# RP2350 register map
Vendor: Raspberry Pi; Series: RP; File version: 0.1
CPU: CM33 r1p0, little endian, MPU, FPU, DSP, VTOR, 4 interrupt priority bits, 52 interrupts, 8 SAU regions
Registers are 32-bit, read-write, reset 0x0 unless marked. A register's access mark holds for its fields unless they carry their own. Offsets are from the block's base; [hi:lo] are bit positions; {n}, {i} and the like mark numbered series; 'fields as' and 'values as' point back to an identical list; <NAME> marks a mode.

## TICKS — Peripheral description
Base 0x40108000
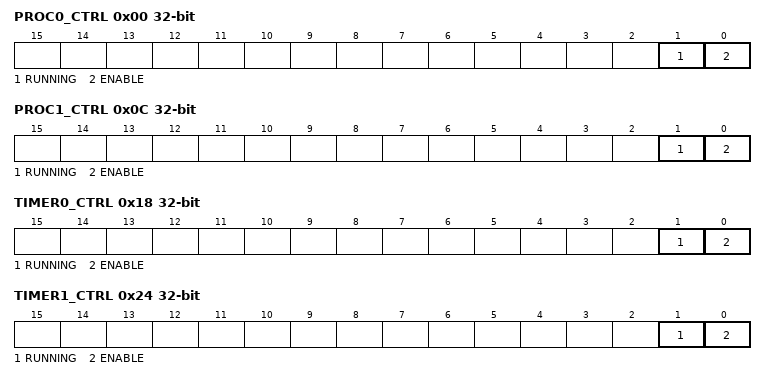
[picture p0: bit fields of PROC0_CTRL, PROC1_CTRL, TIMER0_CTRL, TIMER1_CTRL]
0x00 PROC0_CTRL — Controls the tick generator
  [1] RUNNING ro — Is the tick generator running?
  [0] ENABLE — start / stop tick generation
0x04 PROC0_CYCLES — register description
  [8:0] PROC0_CYCLES — Total number of clk_tick cycles before the next tick.
0x08 PROC0_COUNT reset not defined — register description
  [8:0] PROC0_COUNT ro — Count down timer: the remaining number clk_tick cycles before the next tick is generated.
0x0C PROC1_CTRL — Controls the tick generator
  fields as PROC0_CTRL
0x10 PROC1_CYCLES — register description
  [8:0] PROC1_CYCLES — Total number of clk_tick cycles before the next tick.
0x14 PROC1_COUNT reset not defined — register description
  [8:0] PROC1_COUNT ro — Count down timer: the remaining number clk_tick cycles before the next tick is generated.
0x18 TIMER0_CTRL — Controls the tick generator
  fields as PROC0_CTRL
0x1C TIMER0_CYCLES — register description
  [8:0] TIMER0_CYCLES — Total number of clk_tick cycles before the next tick.
0x20 TIMER0_COUNT reset not defined — register description
  [8:0] TIMER0_COUNT ro — Count down timer: the remaining number clk_tick cycles before the next tick is generated.
0x24 TIMER1_CTRL — Controls the tick generator
  fields as PROC0_CTRL
0x28 TIMER1_CYCLES — register description
  [8:0] TIMER1_CYCLES — Total number of clk_tick cycles before the next tick.
0x2C TIMER1_COUNT reset not defined — register description
  [8:0] TIMER1_COUNT ro — Count down timer: the remaining number clk_tick cycles before the next tick is generated.
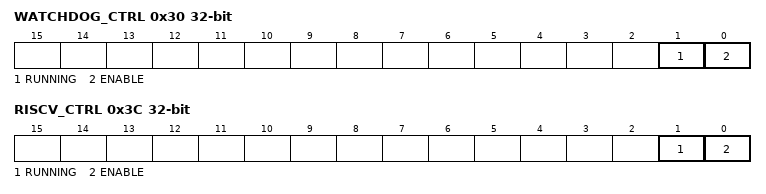
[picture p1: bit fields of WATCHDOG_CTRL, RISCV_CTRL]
0x30 WATCHDOG_CTRL — Controls the tick generator
  fields as PROC0_CTRL
0x34 WATCHDOG_CYCLES — register description
  [8:0] WATCHDOG_CYCLES — Total number of clk_tick cycles before the next tick.
0x38 WATCHDOG_COUNT reset not defined — register description
  [8:0] WATCHDOG_COUNT ro — Count down timer: the remaining number clk_tick cycles before the next tick is generated.
0x3C RISCV_CTRL — Controls the tick generator
  fields as PROC0_CTRL
0x40 RISCV_CYCLES — register description
  [8:0] RISCV_CYCLES — Total number of clk_tick cycles before the next tick.
0x44 RISCV_COUNT reset not defined — register description
  [8:0] RISCV_COUNT ro — Count down timer: the remaining number clk_tick cycles before the next tick is generated.

## PADS_BANK0 — Peripheral description
Base 0x40038000
0x00 VOLTAGE_SELECT — Voltage select. Per bank control
  [0] VOLTAGE_SELECT — Pre-defined description
    0=3v3 (Set voltage to 3.3V (DVDD >= 2V5)); 1=1v8 (Set voltage to 1.8V (DVDD <= 1V8))
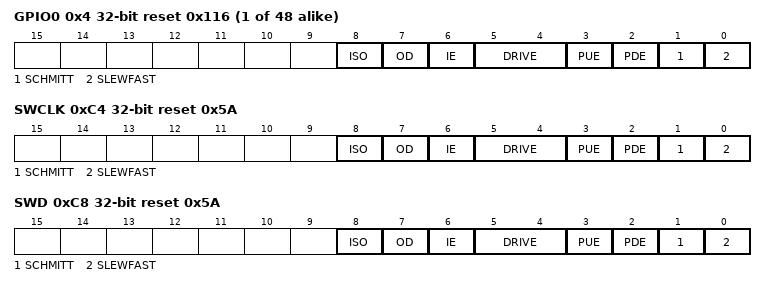
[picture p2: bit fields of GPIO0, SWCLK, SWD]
{0x4+4i} GPIO{i} reset 0x116 (i=0..47) — register description
  [8] ISO — Pad isolation control. Remove this once the pad is configured by software.
  [7] OD — Output disable. Has priority over output enable from peripherals
  [6] IE — Input enable
  [5:4] DRIVE — Drive strength.
    0=2mA; 1=4mA; 2=8mA; 3=12mA
  [3] PUE — Pull up enable
  [2] PDE — Pull down enable
  [1] SCHMITT — Enable schmitt trigger
  [0] SLEWFAST — Slew rate control. 1 = Fast, 0 = Slow
0xC4 SWCLK reset 0x5A — register description
  fields as GPIO0
0xC8 SWD reset 0x5A — register description
  fields as GPIO0

## PADS_QSPI — Peripheral description
Base 0x40040000
0x00 VOLTAGE_SELECT — Voltage select. Per bank control
  [0] VOLTAGE_SELECT — Pre-defined description
    0=3v3 (Set voltage to 3.3V (DVDD >= 2V5)); 1=1v8 (Set voltage to 1.8V (DVDD <= 1V8))
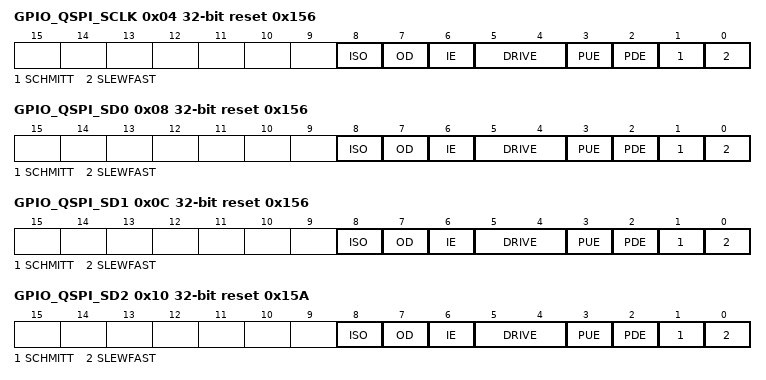
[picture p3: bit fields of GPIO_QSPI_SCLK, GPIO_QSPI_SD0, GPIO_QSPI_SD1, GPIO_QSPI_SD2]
0x04 GPIO_QSPI_SCLK reset 0x156 — register description
  [8] ISO — Pad isolation control. Remove this once the pad is configured by software.
  [7] OD — Output disable. Has priority over output enable from peripherals
  [6] IE — Input enable
  [5:4] DRIVE — Drive strength.
    0=2mA; 1=4mA; 2=8mA; 3=12mA
  [3] PUE — Pull up enable
  [2] PDE — Pull down enable
  [1] SCHMITT — Enable schmitt trigger
  [0] SLEWFAST — Slew rate control. 1 = Fast, 0 = Slow
0x08 GPIO_QSPI_SD0 reset 0x156 — register description
  fields as GPIO_QSPI_SCLK
0x0C GPIO_QSPI_SD1 reset 0x156 — register description
  fields as GPIO_QSPI_SCLK
0x10 GPIO_QSPI_SD2 reset 0x15A — register description
  fields as GPIO_QSPI_SCLK
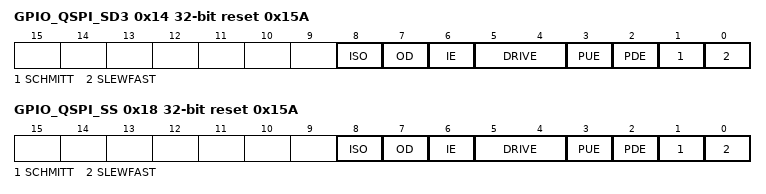
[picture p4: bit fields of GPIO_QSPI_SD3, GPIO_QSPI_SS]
0x14 GPIO_QSPI_SD3 reset 0x15A — register description
  fields as GPIO_QSPI_SCLK
0x18 GPIO_QSPI_SS reset 0x15A — register description
  fields as GPIO_QSPI_SCLK
